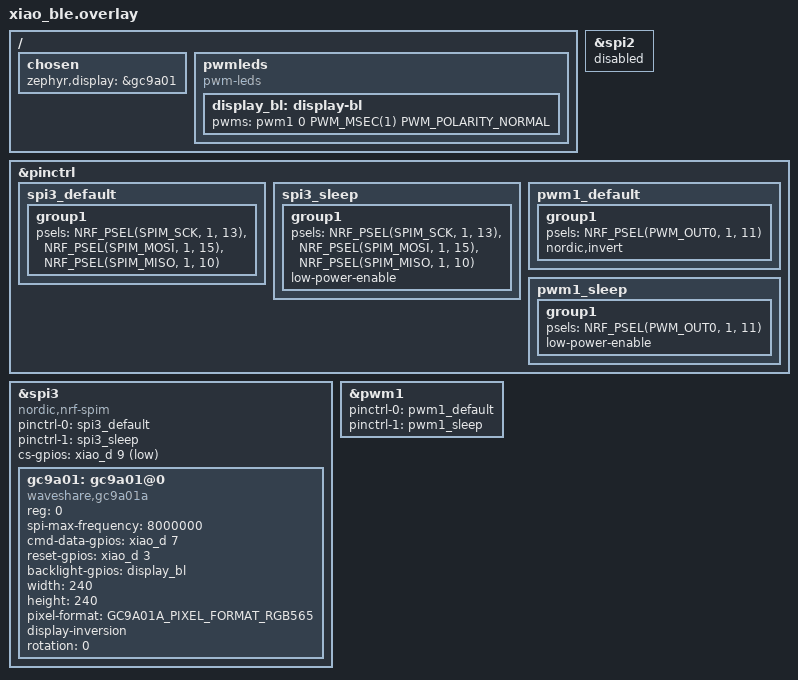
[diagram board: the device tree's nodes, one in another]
#include <zephyr/dt-bindings/display/gc9a01a.h>
#include <dt-bindings/pinctrl/nrf-pinctrl.h>

/ {
    chosen {
        zephyr,display = &gc9a01;
    };

    pwmleds {
        compatible = "pwm-leds";
        display_bl: display-bl {
            pwms = <&pwm1 0 PWM_MSEC(1) PWM_POLARITY_NORMAL>;
        };
    };
};

&spi2 {
    status = "disabled";
};

&pinctrl {
    spi3_default: spi3_default {
        group1 {
            psels = <NRF_PSEL(SPIM_SCK, 1, 13)>,
                <NRF_PSEL(SPIM_MOSI, 1, 15)>,
                <NRF_PSEL(SPIM_MISO, 1, 10)>;
        };
    };

    spi3_sleep: spi3_sleep {
        group1 {
            psels = <NRF_PSEL(SPIM_SCK, 1, 13)>,
                <NRF_PSEL(SPIM_MOSI, 1, 15)>,
                <NRF_PSEL(SPIM_MISO, 1, 10)>;
            low-power-enable;
        };
    };

    pwm1_default: pwm1_default {
        group1 {
            psels = <NRF_PSEL(PWM_OUT0, 1, 11)>;
            nordic,invert;
        };
    };

    pwm1_sleep: pwm1_sleep {
        group1 {
            psels = <NRF_PSEL(PWM_OUT0, 1, 11)>;
            low-power-enable;
        };
    };
};

disp_spi: &spi3 {
    compatible = "nordic,nrf-spim";
    status = "okay";
    pinctrl-0 = <&spi3_default>;
    pinctrl-1 = <&spi3_sleep>;
    pinctrl-names = "default", "sleep";
    cs-gpios = <&xiao_d 9 GPIO_ACTIVE_LOW>;

    gc9a01: gc9a01@0 {
        compatible = "waveshare,gc9a01a";
        status = "okay";
        reg = <0>;
        spi-max-frequency = <8000000>;
        cmd-data-gpios = <&xiao_d 7 GPIO_ACTIVE_HIGH>;
        reset-gpios = <&xiao_d 3 GPIO_ACTIVE_HIGH>;
        backlight-gpios = <&display_bl>;
        width = <240>;
        height = <240>;
        pixel-format = <GC9A01A_PIXEL_FORMAT_RGB565>;
        display-inversion;
        rotation = <0>;
    };
};

&pwm1 {
    status = "okay";
    pinctrl-0 = <&pwm1_default>;
    pinctrl-1 = <&pwm1_sleep>;
    pinctrl-names = "default", "sleep";
};
